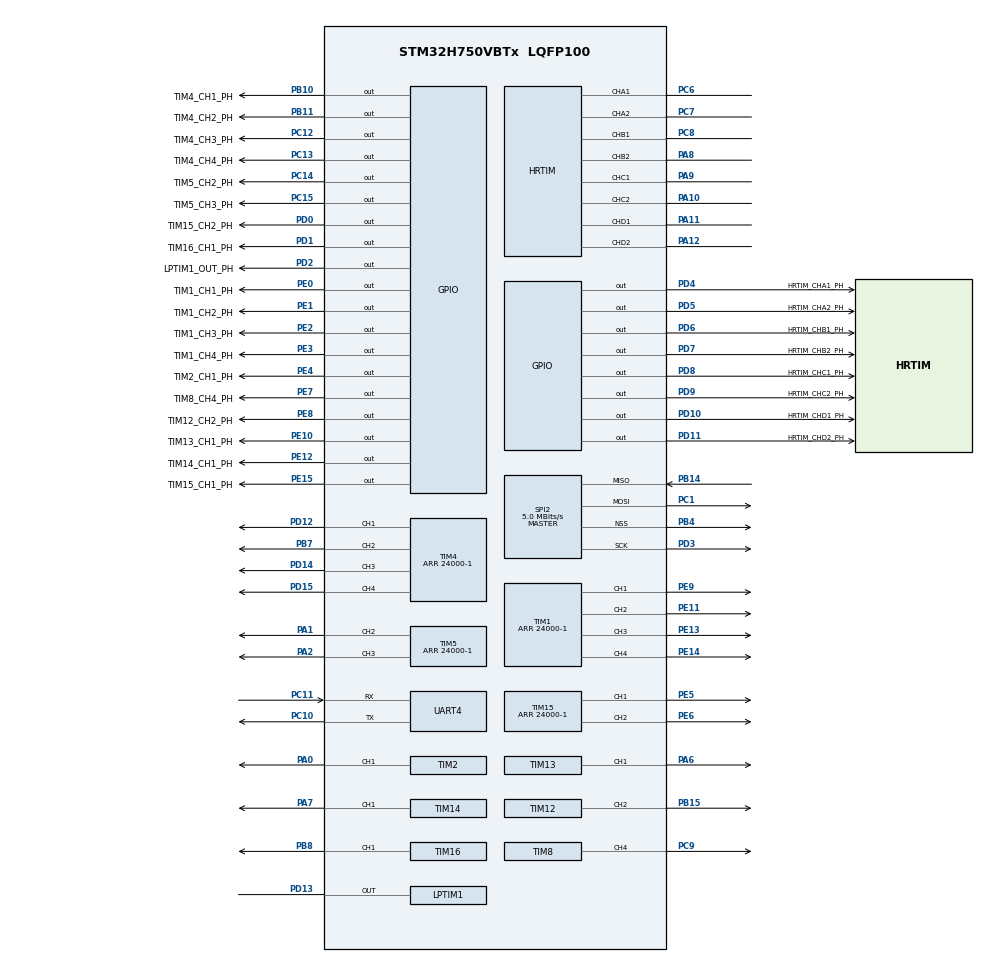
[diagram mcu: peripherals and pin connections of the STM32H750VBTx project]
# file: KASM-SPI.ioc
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CORTEX_M7.default_mode_Activation=1
HRTIM.CaptureUnit1-Output_TA1TA2=__NULL
HRTIM.CompareUnit1-Output_TA1TA2=HRTIM_COMPAREUNIT_1
HRTIM.CompareUnit1-Output_TB1TB2=HRTIM_COMPAREUNIT_1
HRTIM.CompareUnit1-Output_TC1TC2=HRTIM_COMPAREUNIT_1
HRTIM.CompareUnit1-Output_TD1TD2=HRTIM_COMPAREUNIT_1
HRTIM.CompareUnit2-Output_TA1TA2=HRTIM_COMPAREUNIT_2
HRTIM.CompareUnit2-Output_TB1TB2=HRTIM_COMPAREUNIT_2
HRTIM.CompareUnit2-Output_TC1TC2=HRTIM_COMPAREUNIT_2
HRTIM.CompareUnit2-Output_TD1TD2=HRTIM_COMPAREUNIT_2
HRTIM.CompareValue1-Output_TA1TA2=0x00005A00/2
HRTIM.CompareValue1-Output_TB1TB2=0x00005A00/2
HRTIM.CompareValue1-Output_TC1TC2=0x00005A00/2
HRTIM.CompareValue1-Output_TD1TD2=0x00005A00/2
HRTIM.CompareValue2-Output_TA1TA2=0x00005A00/2
HRTIM.CompareValue2-Output_TB1TB2=0x00005A00/2
HRTIM.CompareValue2-Output_TC1TC2=0x00005A00/2
HRTIM.CompareValue2-Output_TD1TD2=0x00005A00/2
HRTIM.Configuration_TA=Waveform
HRTIM.Enable=HRTIM_BURSTMODECTL_DISABLED
HRTIM.Event1-Output_TA1TA2=__NULL
HRTIM.Event_EEV1=HRTIM_EVENT_1
HRTIM.Event_EEV2=__NULL
HRTIM.HalfModeEnable-Output_TA1TA2=HRTIM_HALFMODE_DISABLED
HRTIM.NumberResetSource1-Output_TA1TA2=1
HRTIM.NumberResetSource1-Output_TB1TB2=1
HRTIM.NumberResetSource1-Output_TC1TC2=1
HRTIM.NumberResetSource1-Output_TD1TD2=1
HRTIM.NumberResetSource2_TA=1
HRTIM.NumberResetSource2_TB=1
HRTIM.NumberResetSource2_TC=1
HRTIM.NumberResetSource2_TD=1
HRTIM.NumberResetTrigger-Output_TA1TA2=1
HRTIM.NumberResetTrigger-Output_TB1TB2=1
HRTIM.NumberResetTrigger-Output_TC1TC2=1
HRTIM.NumberResetTrigger-Output_TD1TD2=1
HRTIM.NumberSetSource1-Output_TA1TA2=2
HRTIM.NumberSetSource1-Output_TB1TB2=2
HRTIM.NumberSetSource1-Output_TC1TC2=2
HRTIM.NumberSetSource1-Output_TD1TD2=2
HRTIM.NumberSetSource2_TA=2
HRTIM.NumberSetSource2_TB=2
HRTIM.NumberSetSource2_TC=2
HRTIM.NumberSetSource2_TD=2
HRTIM.NumberUpdateTrigger-Output_TA1TA2=0
HRTIM.Periode_TA=24000-1
HRTIM.Periode_TB=24000-1
HRTIM.Periode_TC=24000-1
HRTIM.Periode_TD=24000-1
HRTIM.Polarity1-Output_TA1TA2=HRTIM_OUTPUTPOLARITY_HIGH
HRTIM.PreloadEnable-Output_TA1TA2=HRTIM_PRELOAD_ENABLED
HRTIM.PreloadEnable-Output_TB1TB2=HRTIM_PRELOAD_ENABLED
HRTIM.PreloadEnable-Output_TC1TC2=HRTIM_PRELOAD_ENABLED
HRTIM.PreloadEnable-Output_TD1TD2=HRTIM_PRELOAD_ENABLED
HRTIM.PrescalerRatio_TA=HRTIM_PRESCALERRATIO_DIV1
HRTIM.PushPull-Output_TA1TA2=HRTIM_TIMPUSHPULLMODE_DISABLED
HRTIM.PushPull-Output_TB1TB2=HRTIM_TIMPUSHPULLMODE_DISABLED
HRTIM.RepetitionUpdate-Output_TA1TA2=HRTIM_UPDATEONREPETITION_DISABLED
HRTIM.ResetOutput1_Source1-Output_TA1TA2=HRTIM_OUTPUTRESET_TIMCMP1
HRTIM.ResetOutput1_Source1-Output_TB1TB2=HRTIM_OUTPUTRESET_TIMCMP1
HRTIM.ResetOutput1_Source1-Output_TC1TC2=HRTIM_OUTPUTRESET_TIMCMP1
HRTIM.ResetOutput1_Source1-Output_TD1TD2=HRTIM_OUTPUTRESET_TIMCMP1
HRTIM.ResetOutput2_Source1-Output_TA1TA2=HRTIM_OUTPUTRESET_TIMCMP2
HRTIM.ResetOutput2_Source1-Output_TB1TB2=HRTIM_OUTPUTRESET_TIMCMP2
HRTIM.ResetOutput2_Source1-Output_TC1TC2=HRTIM_OUTPUTRESET_TIMCMP2
HRTIM.ResetOutput2_Source1-Output_TD1TD2=HRTIM_OUTPUTRESET_TIMCMP2
HRTIM.ResetTrigger1-Output_TA1TA2=HRTIM_TIMRESETTRIGGER_EEV_1
HRTIM.ResetTrigger1-Output_TB1TB2=HRTIM_TIMRESETTRIGGER_EEV_1
HRTIM.ResetTrigger1-Output_TC1TC2=HRTIM_TIMRESETTRIGGER_EEV_1
HRTIM.ResetTrigger1-Output_TD1TD2=HRTIM_TIMRESETTRIGGER_EEV_1
HRTIM.ResetUpdate-Output_TA1TA2=HRTIM_TIMUPDATEONRESET_ENABLED
HRTIM.ResetUpdate-Output_TB1TB2=HRTIM_TIMUPDATEONRESET_ENABLED
HRTIM.ResetUpdate-Output_TC1TC2=HRTIM_TIMUPDATEONRESET_ENABLED
HRTIM.ResetUpdate-Output_TD1TD2=HRTIM_TIMUPDATEONRESET_ENABLED
HRTIM.Sensitivity_EEV1=HRTIM_EVENTSENSITIVITY_RISINGEDGE
HRTIM.SetOutput1_Source1-Output_TA1TA2=HRTIM_OUTPUTSET_EEV_1
HRTIM.SetOutput1_Source1-Output_TB1TB2=HRTIM_OUTPUTSET_EEV_1
HRTIM.SetOutput1_Source1-Output_TC1TC2=HRTIM_OUTPUTSET_EEV_1
HRTIM.SetOutput1_Source1-Output_TD1TD2=HRTIM_OUTPUTSET_EEV_1
HRTIM.SetOutput1_Source2-Output_TA1TA2=HRTIM_OUTPUTSET_TIMPER
HRTIM.SetOutput1_Source2-Output_TB1TB2=HRTIM_OUTPUTSET_TIMPER
HRTIM.SetOutput1_Source2-Output_TC1TC2=HRTIM_OUTPUTSET_TIMPER
HRTIM.SetOutput1_Source2-Output_TD1TD2=HRTIM_OUTPUTSET_TIMPER
HRTIM.SetOutput2_Source1-Output_TA1TA2=HRTIM_OUTPUTSET_EEV_1
HRTIM.SetOutput2_Source1-Output_TB1TB2=HRTIM_OUTPUTSET_EEV_1
HRTIM.SetOutput2_Source1-Output_TC1TC2=HRTIM_OUTPUTSET_EEV_1
HRTIM.SetOutput2_Source1-Output_TD1TD2=HRTIM_OUTPUTSET_EEV_1
HRTIM.SetOutput2_Source2-Output_TA1TA2=HRTIM_OUTPUTSET_TIMPER
HRTIM.SetOutput2_Source2-Output_TB1TB2=HRTIM_OUTPUTSET_TIMPER
HRTIM.SetOutput2_Source2-Output_TC1TC2=HRTIM_OUTPUTSET_TIMPER
HRTIM.SetOutput2_Source2-Output_TD1TD2=HRTIM_OUTPUTSET_TIMPER
HRTIM.Source_EEV1=HRTIM_EVENTSRC_3
HRTIM.StartOnSync-Output_TA1TA2=HRTIM_SYNCSTART_DISABLED
HRTIM.SyncOptions=HRTIM_SYNCOPTION_NONE
LPTIM1.OutputPolarity=LPTIM_OUTPUTPOLARITY_LOW
LPTIM1.TriggerSource=LPTIM_TRIGSOURCE_SOFTWARE
LPTIM1.UpdateMode=LPTIM_UPDATE_IMMEDIATE
Mcu.Family=STM32H7
Mcu.Name=STM32H750VBTx
Mcu.Package=LQFP100
NVIC.LPTIM1_IRQn=true\:0\:0\:false\:false\:true\:true\:true\:true
NVIC.PriorityGroup=NVIC_PRIORITYGROUP_4
NVIC.TIM15_IRQn=true\:0\:0\:false\:false\:true\:true\:true\:true
NVIC.TIM16_IRQn=true\:0\:0\:false\:false\:true\:true\:true\:true
NVIC.TIM1_UP_IRQn=true\:0\:0\:false\:false\:true\:true\:true\:true
NVIC.TIM2_IRQn=true\:0\:0\:false\:false\:true\:true\:true\:true
NVIC.TIM4_IRQn=true\:0\:0\:false\:false\:true\:true\:true\:true
NVIC.TIM5_IRQn=true\:0\:0\:false\:false\:true\:true\:true\:true
NVIC.TIM8_BRK_TIM12_IRQn=true\:0\:0\:false\:false\:true\:true\:true\:true
NVIC.TIM8_TRG_COM_TIM14_IRQn=true\:0\:0\:false\:false\:true\:true\:true\:true
NVIC.TIM8_UP_TIM13_IRQn=true\:0\:0\:false\:false\:true\:true\:true\:true
NVIC.UART4_IRQn=true\:0\:0\:false\:false\:true\:true\:true\:true
PA0.Signal=S_TIM2_CH1_ETR
PA1.Signal=S_TIM5_CH2
PA10.Mode=Output_TC1TC2
PA10.Signal=HRTIM_CHC2
PA11.Mode=Output_TD1TD2
PA11.Signal=HRTIM_CHD1
PA12.Mode=Output_TD1TD2
PA12.Signal=HRTIM_CHD2
PA2.Signal=S_TIM5_CH3
PA6.Signal=S_TIM13_CH1
PA7.Signal=S_TIM14_CH1
PA8.Mode=Output_TB1TB2
PA8.Signal=HRTIM_CHB2
PA9.Mode=Output_TC1TC2
PA9.Signal=HRTIM_CHC1
PB10.GPIO_Label=TIM4_CH1_PH
PB10.Signal=GPIO_Output
PB11.GPIO_Label=TIM4_CH2_PH
PB11.Signal=GPIO_Output
PB14.GPIO_Mode=GPIO_MODE_AF_PP
PB14.GPIO_PuPd=GPIO_NOPULL
PB14.GPIO_Speed=GPIO_SPEED_FREQ_VERY_HIGH
PB14.Mode=Full_Duplex_Master
PB14.Signal=SPI2_MISO
PB15.Signal=S_TIM12_CH2
PB4\ (NJTRST).Mode=NSS_Signal_Hard_Output
PB4\ (NJTRST).Signal=SPI2_NSS
PB7.Signal=S_TIM4_CH2
PB8.Signal=S_TIM16_CH1
PC1.GPIO_Mode=GPIO_MODE_AF_PP
PC1.GPIO_PuPd=GPIO_NOPULL
PC1.GPIO_Speed=GPIO_SPEED_FREQ_VERY_HIGH
PC1.Mode=Full_Duplex_Master
PC1.Signal=SPI2_MOSI
PC10.Mode=Asynchronous
PC10.Signal=UART4_TX
PC11.Mode=Asynchronous
PC11.Signal=UART4_RX
PC12.GPIO_Label=TIM4_CH3_PH
PC12.Signal=GPIO_Output
PC13.GPIO_Label=TIM4_CH4_PH
PC13.Signal=GPIO_Output
PC14-OSC32_IN\ (OSC32_IN).GPIO_Label=TIM5_CH2_PH
PC14-OSC32_IN\ (OSC32_IN).Signal=GPIO_Output
PC15-OSC32_OUT\ (OSC32_OUT).GPIO_Label=TIM5_CH3_PH
PC15-OSC32_OUT\ (OSC32_OUT).Signal=GPIO_Output
PC6.GPIO_Speed_High_Default=GPIO_SPEED_FREQ_VERY_HIGH
PC6.Mode=Output_TA1TA2
PC6.Signal=HRTIM_CHA1
PC7.GPIO_Speed_High_Default=GPIO_SPEED_FREQ_VERY_HIGH
PC7.Mode=Output_TA1TA2
PC7.Signal=HRTIM_CHA2
PC8.Mode=Output_TB1TB2
PC8.Signal=HRTIM_CHB1
PC9.Signal=S_TIM8_CH4
PD0.GPIO_Label=TIM15_CH2_PH
PD0.Signal=GPIO_Output
PD1.GPIO_Label=TIM16_CH1_PH
PD1.Signal=GPIO_Output
PD10.GPIO_Label=HRTIM_CHD1_PH
PD10.Signal=GPIO_Output
PD11.GPIO_Label=HRTIM_CHD2_PH
PD11.Signal=GPIO_Output
PD12.Signal=S_TIM4_CH1
PD13.Mode=WaveformGeneration
PD13.Signal=LPTIM1_OUT
PD14.Signal=S_TIM4_CH3
PD15.Signal=S_TIM4_CH4
PD2.GPIO_Label=LPTIM1_OUT_PH
PD2.Signal=GPIO_Output
PD3.GPIO_Mode=GPIO_MODE_AF_PP
PD3.GPIO_PuPd=GPIO_NOPULL
PD3.GPIO_Speed=GPIO_SPEED_FREQ_VERY_HIGH
PD3.Mode=Full_Duplex_Master
PD3.Signal=SPI2_SCK
PD4.GPIO_Label=HRTIM_CHA1_PH
PD4.Signal=GPIO_Output
PD5.GPIO_Label=HRTIM_CHA2_PH
PD5.Signal=GPIO_Output
PD6.GPIO_Label=HRTIM_CHB1_PH
PD6.Signal=GPIO_Output
PD7.GPIO_Label=HRTIM_CHB2_PH
PD7.Signal=GPIO_Output
PD8.GPIO_Label=HRTIM_CHC1_PH
PD8.Signal=GPIO_Output
PD9.GPIO_Label=HRTIM_CHC2_PH
PD9.Signal=GPIO_Output
PE0.GPIO_Label=TIM1_CH1_PH
PE0.Signal=GPIO_Output
PE1.GPIO_Label=TIM1_CH2_PH
PE1.Signal=GPIO_Output
PE10.GPIO_Label=TIM13_CH1_PH
PE10.Signal=GPIO_Output
PE11.Signal=S_TIM1_CH2
PE12.GPIO_Label=TIM14_CH1_PH
PE12.Signal=GPIO_Output
PE13.Signal=S_TIM1_CH3
PE14.Signal=S_TIM1_CH4
PE15.GPIO_Label=TIM15_CH1_PH
PE15.Signal=GPIO_Output
PE2.GPIO_Label=TIM1_CH3_PH
PE2.Signal=GPIO_Output
PE3.GPIO_Label=TIM1_CH4_PH
PE3.Signal=GPIO_Output
PE4.GPIO_Label=TIM2_CH1_PH
PE4.Signal=GPIO_Output
PE5.Signal=S_TIM15_CH1
PE6.Signal=S_TIM15_CH2
PE7.GPIO_Label=TIM8_CH4_PH
PE7.Signal=GPIO_Output
PE8.GPIO_Label=TIM12_CH2_PH
PE8.Signal=GPIO_Output
PE9.Signal=S_TIM1_CH1
PH0-OSC_IN\ (PH0).Mode=HSE-External-Oscillator
PH0-OSC_IN\ (PH0).Signal=RCC_OSC_IN
PH1-OSC_OUT\ (PH1).Mode=HSE-External-Oscillator
PH1-OSC_OUT\ (PH1).Signal=RCC_OSC_OUT
ProjectManager.HeapSize=0x200
ProjectManager.StackSize=0x400
ProjectManager.TargetToolchain=STM32CubeIDE
RCC.ADCFreq_Value=160000000
RCC.APB1Freq_Value=120000000
RCC.APB2Freq_Value=120000000
RCC.APB3Freq_Value=120000000
RCC.APB4Freq_Value=120000000
RCC.CortexFreq_Value=480000000
RCC.D1PPRE=RCC_APB3_DIV2
RCC.D2PPRE1=RCC_APB1_DIV2
RCC.D2PPRE2=RCC_APB2_DIV2
RCC.D3PPRE=RCC_APB4_DIV2
RCC.DIVM1=2
RCC.DIVM2=2
RCC.DIVN1=80
RCC.DIVN2=80
RCC.DIVP2=6
RCC.DIVQ1=6
RCC.DIVQ2=20
RCC.HCLKFreq_Value=240000000
RCC.HPRE=RCC_HCLK_DIV2
RCC.HSE_VALUE=24000000
RCC.PLLSourceVirtual=RCC_PLLSOURCE_HSE
RCC.RCC_TIM_PRescaler_Selection=RCC_TIMPRES_DESACTIVATED
RCC.SYSCLKFreq_VALUE=480000000
RCC.SYSCLKSource=RCC_SYSCLKSOURCE_PLLCLK
RCC.USBFreq_Value=160000000
SH.S_TIM12_CH2.0=TIM12_CH2,PWM Generation2 CH2
SH.S_TIM13_CH1.0=TIM13_CH1,PWM Generation1 CH1
SH.S_TIM14_CH1.0=TIM14_CH1,PWM Generation1 CH1
SH.S_TIM15_CH1.0=TIM15_CH1,PWM Generation1 CH1
SH.S_TIM15_CH2.0=TIM15_CH2,PWM Generation2 CH2
SH.S_TIM16_CH1.0=TIM16_CH1,PWM Generation1 CH1
SH.S_TIM1_CH1.0=TIM1_CH1,PWM Generation1 CH1
SH.S_TIM1_CH2.0=TIM1_CH2,PWM Generation2 CH2
SH.S_TIM1_CH3.0=TIM1_CH3,PWM Generation3 CH3
SH.S_TIM1_CH4.0=TIM1_CH4,PWM Generation4 CH4
SH.S_TIM2_CH1_ETR.0=TIM2_CH1,PWM Generation1 CH1
SH.S_TIM4_CH1.0=TIM4_CH1,PWM Generation1 CH1
SH.S_TIM4_CH2.0=TIM4_CH2,PWM Generation2 CH2
SH.S_TIM4_CH3.0=TIM4_CH3,PWM Generation3 CH3
SH.S_TIM4_CH4.0=TIM4_CH4,PWM Generation4 CH4
SH.S_TIM5_CH2.0=TIM5_CH2,PWM Generation2 CH2
SH.S_TIM5_CH3.0=TIM5_CH3,PWM Generation3 CH3
SH.S_TIM8_CH4.0=TIM8_CH4,PWM Generation4 CH4
SPI2.BaudRatePrescaler=SPI_BAUDRATEPRESCALER_32
SPI2.CalculateBaudRate=5.0 MBits/s
SPI2.DataSize=SPI_DATASIZE_8BIT
SPI2.Direction=SPI_DIRECTION_2LINES
SPI2.MasterKeepIOState=SPI_MASTER_KEEP_IO_STATE_ENABLE
SPI2.Mode=SPI_MODE_MASTER
SPI2.NSSPMode=SPI_NSS_PULSE_DISABLE
SPI2.VirtualNSS=VM_NSSHARD
SPI2.VirtualType=VM_MASTER
TIM1.AutoReloadPreload=TIM_AUTORELOAD_PRELOAD_ENABLE
TIM1.Channel-PWM\ Generation1\ CH1=TIM_CHANNEL_1
TIM1.Channel-PWM\ Generation2\ CH2=TIM_CHANNEL_2
TIM1.Channel-PWM\ Generation3\ CH3=TIM_CHANNEL_3
TIM1.Channel-PWM\ Generation4\ CH4=TIM_CHANNEL_4
TIM1.Period=24000-1
TIM1.TIM_MasterOutputTrigger=TIM_TRGO_UPDATE
TIM1.TIM_MasterSlaveMode=TIM_MASTERSLAVEMODE_DISABLE
TIM12.AutoReloadPreload=TIM_AUTORELOAD_PRELOAD_ENABLE
TIM12.Channel-PWM\ Generation2\ CH2=TIM_CHANNEL_2
TIM12.Period=24000-1
TIM13.AutoReloadPreload=TIM_AUTORELOAD_PRELOAD_ENABLE
TIM13.Channel=TIM_CHANNEL_1
TIM13.Period=24000-1
TIM14.AutoReloadPreload=TIM_AUTORELOAD_PRELOAD_ENABLE
TIM14.Channel=TIM_CHANNEL_1
TIM14.Period=24000-1
TIM15.AutoReloadPreload=TIM_AUTORELOAD_PRELOAD_ENABLE
TIM15.Channel-PWM\ Generation1\ CH1=TIM_CHANNEL_1
TIM15.Channel-PWM\ Generation2\ CH2=TIM_CHANNEL_2
TIM15.Period=24000-1
TIM16.AutoReloadPreload=TIM_AUTORELOAD_PRELOAD_ENABLE
TIM16.Channel=TIM_CHANNEL_1
TIM16.Period=24000-1
TIM2.AutoReloadPreload=TIM_AUTORELOAD_PRELOAD_ENABLE
TIM2.Channel-PWM\ Generation1\ CH1=TIM_CHANNEL_1
TIM2.Period=24000-1
TIM2.TIM_MasterOutputTrigger=TIM_TRGO_RESET
TIM2.TIM_MasterSlaveMode=TIM_MASTERSLAVEMODE_DISABLE
TIM4.AutoReloadPreload=TIM_AUTORELOAD_PRELOAD_ENABLE
TIM4.Channel-PWM\ Generation1\ CH1=TIM_CHANNEL_1
TIM4.Channel-PWM\ Generation2\ CH2=TIM_CHANNEL_2
TIM4.Channel-PWM\ Generation3\ CH3=TIM_CHANNEL_3
TIM4.Channel-PWM\ Generation4\ CH4=TIM_CHANNEL_4
TIM4.Period=24000-1
TIM5.AutoReloadPreload=TIM_AUTORELOAD_PRELOAD_ENABLE
TIM5.Channel-PWM\ Generation2\ CH2=TIM_CHANNEL_2
TIM5.Channel-PWM\ Generation3\ CH3=TIM_CHANNEL_3
TIM5.Period=24000-1
TIM8.AutoReloadPreload=TIM_AUTORELOAD_PRELOAD_ENABLE
TIM8.Channel-PWM\ Generation4\ CH4=TIM_CHANNEL_4
TIM8.Period=24000-1
UART4.FIFOMode=FIFOMODE_DISABLE
VP_LPTIM1_VS_LPTIM_counterModeInternalClock.Mode=Counts__internal_clock_event_00
VP_MEMORYMAP_VS_MEMORYMAP.Mode=CurAppReg
VP_TIM12_VS_ClockSourceINT.Mode=Internal
VP_TIM13_VS_ClockSourceINT.Mode=Enable_Timer
VP_TIM14_VS_ClockSourceINT.Mode=Enable_Timer
VP_TIM15_VS_ClockSourceINT.Mode=Internal
VP_TIM16_VS_ClockSourceINT.Mode=Enable_Timer
VP_TIM1_VS_ClockSourceINT.Mode=Internal
VP_TIM2_VS_ClockSourceINT.Mode=Internal
VP_TIM4_VS_ClockSourceINT.Mode=Internal
VP_TIM5_VS_ClockSourceINT.Mode=Internal
VP_TIM8_VS_ClockSourceINT.Mode=Internal
board=custom

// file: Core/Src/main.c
/* USER CODE BEGIN Header */
/**
  ******************************************************************************
  * @file           : main.c
  * @brief          : Main program body
  ******************************************************************************
  * @attention
  *
  * Copyright (c) 2025 STMicroelectronics.
  * All rights reserved.
  *
  * This software is licensed under terms that can be found in the LICENSE file
  * in the root directory of this software component.
  * If no LICENSE file comes with this software, it is provided AS-IS.
  *
  ******************************************************************************
  */
/* USER CODE END Header */
#include "main.h"

/* USER CODE BEGIN PM */
/* uncomment below for client board */
#define MASTER_BOARD

/* USER CODE END PM */

HRTIM_HandleTypeDef hhrtim;

LPTIM_HandleTypeDef hlptim1;

SPI_HandleTypeDef hspi2;

TIM_HandleTypeDef htim1;
TIM_HandleTypeDef htim2;
TIM_HandleTypeDef htim4;
TIM_HandleTypeDef htim5;
TIM_HandleTypeDef htim8;
TIM_HandleTypeDef htim12;
TIM_HandleTypeDef htim13;
TIM_HandleTypeDef htim14;
TIM_HandleTypeDef htim15;
TIM_HandleTypeDef htim16;

/* USER CODE BEGIN PV */
/* Buffer used for transmission */
uint8_t TX_Buffer[] = "****SPI - Two Boards communication based on Polling **** SPI Message ******** SPI Message ******** SPI Message ****";

/* Buffer used for reception */
uint8_t RX_Buffer[BUFFERSIZE];
/* USER CODE END PV */

void SystemClock_Config(void);
static void MPU_Config(void);
static void MX_GPIO_Init(void);
static void MX_TIM1_Init(void);
static void MX_TIM2_Init(void);
static void MX_TIM4_Init(void);
static void MX_TIM5_Init(void);
static void MX_TIM8_Init(void);
static void MX_TIM12_Init(void);
static void MX_TIM13_Init(void);
static void MX_TIM14_Init(void);
static void MX_TIM15_Init(void);
static void MX_TIM16_Init(void);
static void MX_HRTIM_Init(void);
static void MX_LPTIM1_Init(void);
static void MX_UART4_Init(void);
static void MX_SPI2_Init(void);
/* USER CODE BEGIN PFP */
/**
* @brief CPU L1-Cache enable.
* @param None
* @retval None
*/
static void CPU_CACHE_Enable(void);

/**
  * @brief  Compares two buffers.
  * @param  pBuffer1, pBuffer2: buffers to be compared.
  * @param  BufferLength: buffer's length
  * @retval 0  : pBuffer1 identical to pBuffer2
  *         >0 : pBuffer1 differs from pBuffer2
  */
static uint16_t Buffercmp(uint8_t* pBuffer1, uint8_t* pBuffer2, uint16_t BufferLength);

/* USER CODE END PFP */

int main(void)
{

  /* MPU Configuration--------------------------------------------------------*/
  MPU_Config();

  /* MCU Configuration--------------------------------------------------------*/

  /* Reset of all peripherals, Initializes the Flash interface and the Systick. */
  HAL_Init();

  /* Configure the system clock */
  SystemClock_Config();

  /* Initialize all configured peripherals */
  MX_GPIO_Init();
  MX_TIM1_Init();
  MX_TIM2_Init();
  MX_TIM4_Init();
  MX_TIM5_Init();
  MX_TIM8_Init();
  MX_TIM12_Init();
  MX_TIM13_Init();
  MX_TIM14_Init();
  MX_TIM15_Init();
  MX_TIM16_Init();
  MX_HRTIM_Init();
  MX_LPTIM1_Init();
  MX_UART4_Init();
  MX_SPI2_Init();

  /* Infinite loop */
  /* USER CODE BEGIN WHILE */
  while (1)
  {

	  /* While the SPI in TransmitReceive process, user can transmit data through
	     "TX_Buffer" buffer & receive data through "RX_Buffer" */
	  /* Timeout is set to 5S */

	  switch(HAL_SPI_TransmitReceive(&hspi2, (uint8_t*)TX_Buffer, (uint8_t *)RX_Buffer, BUFFERSIZE, 5000))
	  {
	    case HAL_OK:
	      /* Communication is completed ___________________________________________ */
	      /* Compare the sent and received buffers */
//	      if (Buffercmp((uint8_t *)TX_Buffer, (uint8_t *)RX_Buffer, BUFFERSIZE))
//	      {
//	        /* Transfer error in transmission process */
//	        Error_Handler();
//	      }
	      break;

	    case HAL_TIMEOUT:
	      /* A Timeout Occur ______________________________________________________*/
	      /* Call Timeout Handler */
	    	HAL_Delay(1);
	    	Error_Handler();
	      break;
	      /* An Error Occur ______________________________________________________ */
	    case HAL_ERROR:
	      /* Call Error Handler */
	      Error_Handler();
	      break;
	    default:
	      break;
	  }

	  HAL_Delay(100); // wait a couple seconds
    /* USER CODE END WHILE */

  }
}

void SystemClock_Config(void)
{
  RCC_OscInitTypeDef RCC_OscInitStruct = {0};
  RCC_ClkInitTypeDef RCC_ClkInitStruct = {0};

  /** Supply configuration update enable
  */
  HAL_PWREx_ConfigSupply(PWR_LDO_SUPPLY);

  /** Configure the main internal regulator output voltage
  */
  __HAL_PWR_VOLTAGESCALING_CONFIG(PWR_REGULATOR_VOLTAGE_SCALE0);

  while(!__HAL_PWR_GET_FLAG(PWR_FLAG_VOSRDY)) {}

  /** Initializes the RCC Oscillators according to the specified parameters
  * in the RCC_OscInitTypeDef structure.
  */
  RCC_OscInitStruct.OscillatorType = RCC_OSCILLATORTYPE_HSE;
  RCC_OscInitStruct.HSEState = RCC_HSE_ON;
  RCC_OscInitStruct.PLL.PLLState = RCC_PLL_ON;
  RCC_OscInitStruct.PLL.PLLSource = RCC_PLLSOURCE_HSE;
  RCC_OscInitStruct.PLL.PLLM = 2;
  RCC_OscInitStruct.PLL.PLLN = 80;
  RCC_OscInitStruct.PLL.PLLP = 2;
  RCC_OscInitStruct.PLL.PLLQ = 6;
  RCC_OscInitStruct.PLL.PLLR = 2;
  RCC_OscInitStruct.PLL.PLLRGE = RCC_PLL1VCIRANGE_3;
  RCC_OscInitStruct.PLL.PLLVCOSEL = RCC_PLL1VCOWIDE;
  RCC_OscInitStruct.PLL.PLLFRACN = 0;
  if (HAL_RCC_OscConfig(&RCC_OscInitStruct) != HAL_OK)
  {
    Error_Handler();
  }

  /** Initializes the CPU, AHB and APB buses clocks
  */
  RCC_ClkInitStruct.ClockType = RCC_CLOCKTYPE_HCLK|RCC_CLOCKTYPE_SYSCLK
                              |RCC_CLOCKTYPE_PCLK1|RCC_CLOCKTYPE_PCLK2
                              |RCC_CLOCKTYPE_D3PCLK1|RCC_CLOCKTYPE_D1PCLK1;
  RCC_ClkInitStruct.SYSCLKSource = RCC_SYSCLKSOURCE_PLLCLK;
  RCC_ClkInitStruct.SYSCLKDivider = RCC_SYSCLK_DIV1;
  RCC_ClkInitStruct.AHBCLKDivider = RCC_HCLK_DIV2;
  RCC_ClkInitStruct.APB3CLKDivider = RCC_APB3_DIV2;
  RCC_ClkInitStruct.APB1CLKDivider = RCC_APB1_DIV2;
  RCC_ClkInitStruct.APB2CLKDivider = RCC_APB2_DIV2;
  RCC_ClkInitStruct.APB4CLKDivider = RCC_APB4_DIV2;

  if (HAL_RCC_ClockConfig(&RCC_ClkInitStruct, FLASH_LATENCY_4) != HAL_OK)
  {
    Error_Handler();
  }
}

static void MX_HRTIM_Init(void)
{

  HRTIM_EventCfgTypeDef pEventCfg = {0};
  HRTIM_TimeBaseCfgTypeDef pTimeBaseCfg = {0};
  HRTIM_TimerCfgTypeDef pTimerCfg = {0};
  HRTIM_CompareCfgTypeDef pCompareCfg = {0};
  HRTIM_OutputCfgTypeDef pOutputCfg = {0};

  hhrtim.Instance = HRTIM1;
  hhrtim.Init.HRTIMInterruptResquests = HRTIM_IT_NONE;
  hhrtim.Init.SyncOptions = HRTIM_SYNCOPTION_NONE;
  if (HAL_HRTIM_Init(&hhrtim) != HAL_OK)
  {
    Error_Handler();
  }
  if (HAL_HRTIM_EventPrescalerConfig(&hhrtim, HRTIM_EVENTPRESCALER_DIV1) != HAL_OK)
  {
    Error_Handler();
  }
  pEventCfg.Source = HRTIM_EVENTSRC_3;
  pEventCfg.Polarity = HRTIM_EVENTPOLARITY_HIGH;
  pEventCfg.Sensitivity = HRTIM_EVENTSENSITIVITY_RISINGEDGE;
  pEventCfg.FastMode = HRTIM_EVENTFASTMODE_DISABLE;
  if (HAL_HRTIM_EventConfig(&hhrtim, HRTIM_EVENT_1, &pEventCfg) != HAL_OK)
  {
    Error_Handler();
  }
  pTimeBaseCfg.Period = 24000-1;
  pTimeBaseCfg.RepetitionCounter = 0x00;
  pTimeBaseCfg.PrescalerRatio = HRTIM_PRESCALERRATIO_DIV1;
  pTimeBaseCfg.Mode = HRTIM_MODE_CONTINUOUS;
  if (HAL_HRTIM_TimeBaseConfig(&hhrtim, HRTIM_TIMERINDEX_TIMER_A, &pTimeBaseCfg) != HAL_OK)
  {
    Error_Handler();
  }
  pTimerCfg.InterruptRequests = HRTIM_TIM_IT_NONE;
  pTimerCfg.DMARequests = HRTIM_TIM_DMA_NONE;
  pTimerCfg.DMASrcAddress = 0x0000;
  pTimerCfg.DMADstAddress = 0x0000;
  pTimerCfg.DMASize = 0x1;
  pTimerCfg.HalfModeEnable = HRTIM_HALFMODE_DISABLED;
  pTimerCfg.StartOnSync = HRTIM_SYNCSTART_DISABLED;
  pTimerCfg.ResetOnSync = HRTIM_SYNCRESET_DISABLED;
  pTimerCfg.DACSynchro = HRTIM_DACSYNC_NONE;
  pTimerCfg.PreloadEnable = HRTIM_PRELOAD_ENABLED;
  pTimerCfg.UpdateGating = HRTIM_UPDATEGATING_INDEPENDENT;
  pTimerCfg.BurstMode = HRTIM_TIMERBURSTMODE_MAINTAINCLOCK;
  pTimerCfg.RepetitionUpdate = HRTIM_UPDATEONREPETITION_DISABLED;
  pTimerCfg.PushPull = HRTIM_TIMPUSHPULLMODE_DISABLED;
  pTimerCfg.FaultEnable = HRTIM_TIMFAULTENABLE_NONE;
  pTimerCfg.FaultLock = HRTIM_TIMFAULTLOCK_READWRITE;
  pTimerCfg.DeadTimeInsertion = HRTIM_TIMDEADTIMEINSERTION_DISABLED;
  pTimerCfg.DelayedProtectionMode = HRTIM_TIMER_A_B_C_DELAYEDPROTECTION_DISABLED;
  pTimerCfg.UpdateTrigger = HRTIM_TIMUPDATETRIGGER_NONE;
  pTimerCfg.ResetTrigger = HRTIM_TIMRESETTRIGGER_EEV_1;
  pTimerCfg.ResetUpdate = HRTIM_TIMUPDATEONRESET_ENABLED;
  if (HAL_HRTIM_WaveformTimerConfig(&hhrtim, HRTIM_TIMERINDEX_TIMER_A, &pTimerCfg) != HAL_OK)
  {
    Error_Handler();
  }
  if (HAL_HRTIM_WaveformTimerConfig(&hhrtim, HRTIM_TIMERINDEX_TIMER_B, &pTimerCfg) != HAL_OK)
  {
    Error_Handler();
  }
  if (HAL_HRTIM_WaveformTimerConfig(&hhrtim, HRTIM_TIMERINDEX_TIMER_C, &pTimerCfg) != HAL_OK)
  {
    Error_Handler();
  }
  pTimerCfg.DelayedProtectionMode = HRTIM_TIMER_D_E_DELAYEDPROTECTION_DISABLED;
  if (HAL_HRTIM_WaveformTimerConfig(&hhrtim, HRTIM_TIMERINDEX_TIMER_D, &pTimerCfg) != HAL_OK)
  {
    Error_Handler();
  }
  pCompareCfg.CompareValue = 0x00005A00/2;
  if (HAL_HRTIM_WaveformCompareConfig(&hhrtim, HRTIM_TIMERINDEX_TIMER_A, HRTIM_COMPAREUNIT_1, &pCompareCfg) != HAL_OK)
  {
    Error_Handler();
  }
  pCompareCfg.AutoDelayedMode = HRTIM_AUTODELAYEDMODE_REGULAR;
  pCompareCfg.AutoDelayedTimeout = 0x0000;

  if (HAL_HRTIM_WaveformCompareConfig(&hhrtim, HRTIM_TIMERINDEX_TIMER_A, HRTIM_COMPAREUNIT_2, &pCompareCfg) != HAL_OK)
  {
    Error_Handler();
  }

  if (HAL_HRTIM_WaveformCompareConfig(&hhrtim, HRTIM_TIMERINDEX_TIMER_B, HRTIM_COMPAREUNIT_2, &pCompareCfg) != HAL_OK)
  {
    Error_Handler();
  }

  if (HAL_HRTIM_WaveformCompareConfig(&hhrtim, HRTIM_TIMERINDEX_TIMER_C, HRTIM_COMPAREUNIT_2, &pCompareCfg) != HAL_OK)
  {
    Error_Handler();
  }

  if (HAL_HRTIM_WaveformCompareConfig(&hhrtim, HRTIM_TIMERINDEX_TIMER_D, HRTIM_COMPAREUNIT_2, &pCompareCfg) != HAL_OK)
  {
    Error_Handler();
  }
  pOutputCfg.Polarity = HRTIM_OUTPUTPOLARITY_HIGH;
  pOutputCfg.SetSource = HRTIM_OUTPUTSET_EEV_1|HRTIM_OUTPUTSET_TIMPER;
  pOutputCfg.ResetSource = HRTIM_OUTPUTRESET_TIMCMP1;
  pOutputCfg.IdleMode = HRTIM_OUTPUTIDLEMODE_NONE;
  pOutputCfg.IdleLevel = HRTIM_OUTPUTIDLELEVEL_INACTIVE;
  pOutputCfg.FaultLevel = HRTIM_OUTPUTFAULTLEVEL_NONE;
  pOutputCfg.ChopperModeEnable = HRTIM_OUTPUTCHOPPERMODE_DISABLED;
  pOutputCfg.BurstModeEntryDelayed = HRTIM_OUTPUTBURSTMODEENTRY_REGULAR;
  if (HAL_HRTIM_WaveformOutputConfig(&hhrtim, HRTIM_TIMERINDEX_TIMER_A, HRTIM_OUTPUT_TA1, &pOutputCfg) != HAL_OK)
  {
    Error_Handler();
  }
  if (HAL_HRTIM_WaveformOutputConfig(&hhrtim, HRTIM_TIMERINDEX_TIMER_B, HRTIM_OUTPUT_TB1, &pOutputCfg) != HAL_OK)
  {
    Error_Handler();
  }
  if (HAL_HRTIM_WaveformOutputConfig(&hhrtim, HRTIM_TIMERINDEX_TIMER_C, HRTIM_OUTPUT_TC1, &pOutputCfg) != HAL_OK)
  {
    Error_Handler();
  }
  if (HAL_HRTIM_WaveformOutputConfig(&hhrtim, HRTIM_TIMERINDEX_TIMER_D, HRTIM_OUTPUT_TD1, &pOutputCfg) != HAL_OK)
  {
    Error_Handler();
  }
  pOutputCfg.ResetSource = HRTIM_OUTPUTRESET_TIMCMP2;
  if (HAL_HRTIM_WaveformOutputConfig(&hhrtim, HRTIM_TIMERINDEX_TIMER_A, HRTIM_OUTPUT_TA2, &pOutputCfg) != HAL_OK)
  {
    Error_Handler();
  }
  if (HAL_HRTIM_WaveformOutputConfig(&hhrtim, HRTIM_TIMERINDEX_TIMER_B, HRTIM_OUTPUT_TB2, &pOutputCfg) != HAL_OK)
  {
    Error_Handler();
  }
  if (HAL_HRTIM_WaveformOutputConfig(&hhrtim, HRTIM_TIMERINDEX_TIMER_C, HRTIM_OUTPUT_TC2, &pOutputCfg) != HAL_OK)
  {
    Error_Handler();
  }
  if (HAL_HRTIM_WaveformOutputConfig(&hhrtim, HRTIM_TIMERINDEX_TIMER_D, HRTIM_OUTPUT_TD2, &pOutputCfg) != HAL_OK)
  {
    Error_Handler();
  }
  if (HAL_HRTIM_TimeBaseConfig(&hhrtim, HRTIM_TIMERINDEX_TIMER_B, &pTimeBaseCfg) != HAL_OK)
  {
    Error_Handler();
  }
  if (HAL_HRTIM_WaveformCompareConfig(&hhrtim, HRTIM_TIMERINDEX_TIMER_B, HRTIM_COMPAREUNIT_1, &pCompareCfg) != HAL_OK)
  {
    Error_Handler();
  }
  if (HAL_HRTIM_TimeBaseConfig(&hhrtim, HRTIM_TIMERINDEX_TIMER_C, &pTimeBaseCfg) != HAL_OK)
  {
    Error_Handler();
  }
  if (HAL_HRTIM_WaveformCompareConfig(&hhrtim, HRTIM_TIMERINDEX_TIMER_C, HRTIM_COMPAREUNIT_1, &pCompareCfg) != HAL_OK)
  {
    Error_Handler();
  }
  if (HAL_HRTIM_TimeBaseConfig(&hhrtim, HRTIM_TIMERINDEX_TIMER_D, &pTimeBaseCfg) != HAL_OK)
  {
    Error_Handler();
  }
  if (HAL_HRTIM_WaveformCompareConfig(&hhrtim, HRTIM_TIMERINDEX_TIMER_D, HRTIM_COMPAREUNIT_1, &pCompareCfg) != HAL_OK)
  {
    Error_Handler();
  }
  HAL_HRTIM_MspPostInit(&hhrtim);

}

static void MX_LPTIM1_Init(void)
{

  hlptim1.Instance = LPTIM1;
  hlptim1.Init.Clock.Source = LPTIM_CLOCKSOURCE_APBCLOCK_LPOSC;
  hlptim1.Init.Clock.Prescaler = LPTIM_PRESCALER_DIV1;
  hlptim1.Init.Trigger.Source = LPTIM_TRIGSOURCE_SOFTWARE;
  hlptim1.Init.OutputPolarity = LPTIM_OUTPUTPOLARITY_LOW;
  hlptim1.Init.UpdateMode = LPTIM_UPDATE_IMMEDIATE;
  hlptim1.Init.CounterSource = LPTIM_COUNTERSOURCE_INTERNAL;
  hlptim1.Init.Input1Source = LPTIM_INPUT1SOURCE_GPIO;
  hlptim1.Init.Input2Source = LPTIM_INPUT2SOURCE_GPIO;
  if (HAL_LPTIM_Init(&hlptim1) != HAL_OK)
  {
    Error_Handler();
  }

}

static void MX_SPI2_Init(void)
{

  /* USER CODE BEGIN SPI2_Init 1 */
#ifdef MASTER_BOARD
  hspi2.Init.Mode = SPI_MODE_MASTER;
#else
  hspi2.Init.Mode = SPI_MODE_SLAVE;
#endif /* MASTER_BOARD */

  /* USER CODE END SPI2_Init 1 */
  /* SPI2 parameter configuration*/
  hspi2.Instance = SPI2;
  hspi2.Init.Mode = SPI_MODE_MASTER;
  hspi2.Init.Direction = SPI_DIRECTION_2LINES;
  hspi2.Init.DataSize = SPI_DATASIZE_8BIT;
  hspi2.Init.CLKPolarity = SPI_POLARITY_LOW;
  hspi2.Init.CLKPhase = SPI_PHASE_1EDGE;
  hspi2.Init.NSS = SPI_NSS_HARD_OUTPUT;
  hspi2.Init.BaudRatePrescaler = SPI_BAUDRATEPRESCALER_32;
  hspi2.Init.FirstBit = SPI_FIRSTBIT_MSB;
  hspi2.Init.TIMode = SPI_TIMODE_DISABLE;
  hspi2.Init.CRCCalculation = SPI_CRCCALCULATION_DISABLE;
  hspi2.Init.CRCPolynomial = 0x0;
  hspi2.Init.NSSPMode = SPI_NSS_PULSE_DISABLE;
  hspi2.Init.NSSPolarity = SPI_NSS_POLARITY_LOW;
  hspi2.Init.FifoThreshold = SPI_FIFO_THRESHOLD_01DATA;
  hspi2.Init.TxCRCInitializationPattern = SPI_CRC_INITIALIZATION_ALL_ZERO_PATTERN;
  hspi2.Init.RxCRCInitializationPattern = SPI_CRC_INITIALIZATION_ALL_ZERO_PATTERN;
  hspi2.Init.MasterSSIdleness = SPI_MASTER_SS_IDLENESS_00CYCLE;
  hspi2.Init.MasterInterDataIdleness = SPI_MASTER_INTERDATA_IDLENESS_00CYCLE;
  hspi2.Init.MasterReceiverAutoSusp = SPI_MASTER_RX_AUTOSUSP_DISABLE;
  hspi2.Init.MasterKeepIOState = SPI_MASTER_KEEP_IO_STATE_ENABLE;
  hspi2.Init.IOSwap = SPI_IO_SWAP_DISABLE;
  if (HAL_SPI_Init(&hspi2) != HAL_OK)
  {
    Error_Handler();
  }

}

static void MX_TIM1_Init(void)
{

  TIM_ClockConfigTypeDef sClockSourceConfig = {0};
  TIM_MasterConfigTypeDef sMasterConfig = {0};
  TIM_OC_InitTypeDef sConfigOC = {0};
  TIM_BreakDeadTimeConfigTypeDef sBreakDeadTimeConfig = {0};

  htim1.Instance = TIM1;
  htim1.Init.Prescaler = 0;
  htim1.Init.CounterMode = TIM_COUNTERMODE_UP;
  htim1.Init.Period = 24000-1;
  htim1.Init.ClockDivision = TIM_CLOCKDIVISION_DIV1;
  htim1.Init.RepetitionCounter = 0;
  htim1.Init.AutoReloadPreload = TIM_AUTORELOAD_PRELOAD_ENABLE;
  if (HAL_TIM_Base_Init(&htim1) != HAL_OK)
  {
    Error_Handler();
  }
  sClockSourceConfig.ClockSource = TIM_CLOCKSOURCE_INTERNAL;
  if (HAL_TIM_ConfigClockSource(&htim1, &sClockSourceConfig) != HAL_OK)
  {
    Error_Handler();
  }
  if (HAL_TIM_PWM_Init(&htim1) != HAL_OK)
  {
    Error_Handler();
  }
  sMasterConfig.MasterOutputTrigger = TIM_TRGO_UPDATE;
  sMasterConfig.MasterOutputTrigger2 = TIM_TRGO2_RESET;
  sMasterConfig.MasterSlaveMode = TIM_MASTERSLAVEMODE_DISABLE;
  if (HAL_TIMEx_MasterConfigSynchronization(&htim1, &sMasterConfig) != HAL_OK)
  {
    Error_Handler();
  }
  sConfigOC.OCMode = TIM_OCMODE_PWM1;
  sConfigOC.Pulse = 0;
  sConfigOC.OCPolarity = TIM_OCPOLARITY_HIGH;
  sConfigOC.OCNPolarity = TIM_OCNPOLARITY_HIGH;
  sConfigOC.OCFastMode = TIM_OCFAST_DISABLE;
  sConfigOC.OCIdleState = TIM_OCIDLESTATE_RESET;
  sConfigOC.OCNIdleState = TIM_OCNIDLESTATE_RESET;
  if (HAL_TIM_PWM_ConfigChannel(&htim1, &sConfigOC, TIM_CHANNEL_1) != HAL_OK)
  {
    Error_Handler();
  }
  if (HAL_TIM_PWM_ConfigChannel(&htim1, &sConfigOC, TIM_CHANNEL_2) != HAL_OK)
  {
    Error_Handler();
  }
  if (HAL_TIM_PWM_ConfigChannel(&htim1, &sConfigOC, TIM_CHANNEL_3) != HAL_OK)
  {
    Error_Handler();
  }
  if (HAL_TIM_PWM_ConfigChannel(&htim1, &sConfigOC, TIM_CHANNEL_4) != HAL_OK)
  {
    Error_Handler();
  }
  sBreakDeadTimeConfig.OffStateRunMode = TIM_OSSR_DISABLE;
  sBreakDeadTimeConfig.OffStateIDLEMode = TIM_OSSI_DISABLE;
  sBreakDeadTimeConfig.LockLevel = TIM_LOCKLEVEL_OFF;
  sBreakDeadTimeConfig.DeadTime = 0;
  sBreakDeadTimeConfig.BreakState = TIM_BREAK_DISABLE;
  sBreakDeadTimeConfig.BreakPolarity = TIM_BREAKPOLARITY_HIGH;
  sBreakDeadTimeConfig.BreakFilter = 0;
  sBreakDeadTimeConfig.Break2State = TIM_BREAK2_DISABLE;
  sBreakDeadTimeConfig.Break2Polarity = TIM_BREAK2POLARITY_HIGH;
  sBreakDeadTimeConfig.Break2Filter = 0;
  sBreakDeadTimeConfig.AutomaticOutput = TIM_AUTOMATICOUTPUT_DISABLE;
  if (HAL_TIMEx_ConfigBreakDeadTime(&htim1, &sBreakDeadTimeConfig) != HAL_OK)
  {
    Error_Handler();
  }
  HAL_TIM_MspPostInit(&htim1);

}

static void MX_TIM2_Init(void)
{

  TIM_ClockConfigTypeDef sClockSourceConfig = {0};
  TIM_MasterConfigTypeDef sMasterConfig = {0};
  TIM_OC_InitTypeDef sConfigOC = {0};

  htim2.Instance = TIM2;
  htim2.Init.Prescaler = 0;
  htim2.Init.CounterMode = TIM_COUNTERMODE_UP;
  htim2.Init.Period = 24000-1;
  htim2.Init.ClockDivision = TIM_CLOCKDIVISION_DIV1;
  htim2.Init.AutoReloadPreload = TIM_AUTORELOAD_PRELOAD_ENABLE;
  if (HAL_TIM_Base_Init(&htim2) != HAL_OK)
  {
    Error_Handler();
  }
  sClockSourceConfig.ClockSource = TIM_CLOCKSOURCE_INTERNAL;
  if (HAL_TIM_ConfigClockSource(&htim2, &sClockSourceConfig) != HAL_OK)
  {
    Error_Handler();
  }
  if (HAL_TIM_PWM_Init(&htim2) != HAL_OK)
  {
    Error_Handler();
  }
  sMasterConfig.MasterOutputTrigger = TIM_TRGO_RESET;
  sMasterConfig.MasterSlaveMode = TIM_MASTERSLAVEMODE_DISABLE;
  if (HAL_TIMEx_MasterConfigSynchronization(&htim2, &sMasterConfig) != HAL_OK)
  {
    Error_Handler();
  }
  sConfigOC.OCMode = TIM_OCMODE_PWM1;
  sConfigOC.Pulse = 0;
  sConfigOC.OCPolarity = TIM_OCPOLARITY_HIGH;
  sConfigOC.OCFastMode = TIM_OCFAST_DISABLE;
  if (HAL_TIM_PWM_ConfigChannel(&htim2, &sConfigOC, TIM_CHANNEL_1) != HAL_OK)
  {
    Error_Handler();
  }
  HAL_TIM_MspPostInit(&htim2);

}

static void MX_TIM4_Init(void)
{

  TIM_ClockConfigTypeDef sClockSourceConfig = {0};
  TIM_MasterConfigTypeDef sMasterConfig = {0};
  TIM_OC_InitTypeDef sConfigOC = {0};

  htim4.Instance = TIM4;
  htim4.Init.Prescaler = 0;
  htim4.Init.CounterMode = TIM_COUNTERMODE_UP;
  htim4.Init.Period = 24000-1;
  htim4.Init.ClockDivision = TIM_CLOCKDIVISION_DIV1;
  htim4.Init.AutoReloadPreload = TIM_AUTORELOAD_PRELOAD_ENABLE;
  if (HAL_TIM_Base_Init(&htim4) != HAL_OK)
  {
    Error_Handler();
  }
  sClockSourceConfig.ClockSource = TIM_CLOCKSOURCE_INTERNAL;
  if (HAL_TIM_ConfigClockSource(&htim4, &sClockSourceConfig) != HAL_OK)
  {
    Error_Handler();
  }
  if (HAL_TIM_PWM_Init(&htim4) != HAL_OK)
  {
    Error_Handler();
  }
  sMasterConfig.MasterOutputTrigger = TIM_TRGO_RESET;
  sMasterConfig.MasterSlaveMode = TIM_MASTERSLAVEMODE_DISABLE;
  if (HAL_TIMEx_MasterConfigSynchronization(&htim4, &sMasterConfig) != HAL_OK)
  {
    Error_Handler();
  }
  sConfigOC.OCMode = TIM_OCMODE_PWM1;
  sConfigOC.Pulse = 0;
  sConfigOC.OCPolarity = TIM_OCPOLARITY_HIGH;
  sConfigOC.OCFastMode = TIM_OCFAST_DISABLE;
  if (HAL_TIM_PWM_ConfigChannel(&htim4, &sConfigOC, TIM_CHANNEL_1) != HAL_OK)
  {
    Error_Handler();
  }
  if (HAL_TIM_PWM_ConfigChannel(&htim4, &sConfigOC, TIM_CHANNEL_2) != HAL_OK)
  {
    Error_Handler();
  }
  if (HAL_TIM_PWM_ConfigChannel(&htim4, &sConfigOC, TIM_CHANNEL_3) != HAL_OK)
  {
    Error_Handler();
  }
  if (HAL_TIM_PWM_ConfigChannel(&htim4, &sConfigOC, TIM_CHANNEL_4) != HAL_OK)
  {
    Error_Handler();
  }
  HAL_TIM_MspPostInit(&htim4);

}

static void MX_TIM5_Init(void)
{

  TIM_ClockConfigTypeDef sClockSourceConfig = {0};
  TIM_MasterConfigTypeDef sMasterConfig = {0};
  TIM_OC_InitTypeDef sConfigOC = {0};

  htim5.Instance = TIM5;
  htim5.Init.Prescaler = 0;
  htim5.Init.CounterMode = TIM_COUNTERMODE_UP;
  htim5.Init.Period = 24000-1;
  htim5.Init.ClockDivision = TIM_CLOCKDIVISION_DIV1;
  htim5.Init.AutoReloadPreload = TIM_AUTORELOAD_PRELOAD_ENABLE;
  if (HAL_TIM_Base_Init(&htim5) != HAL_OK)
  {
    Error_Handler();
  }
  sClockSourceConfig.ClockSource = TIM_CLOCKSOURCE_INTERNAL;
  if (HAL_TIM_ConfigClockSource(&htim5, &sClockSourceConfig) != HAL_OK)
  {
    Error_Handler();
  }
  if (HAL_TIM_PWM_Init(&htim5) != HAL_OK)
  {
    Error_Handler();
  }
  sMasterConfig.MasterOutputTrigger = TIM_TRGO_RESET;
  sMasterConfig.MasterSlaveMode = TIM_MASTERSLAVEMODE_DISABLE;
  if (HAL_TIMEx_MasterConfigSynchronization(&htim5, &sMasterConfig) != HAL_OK)
  {
    Error_Handler();
  }
  sConfigOC.OCMode = TIM_OCMODE_PWM1;
  sConfigOC.Pulse = 0;
  sConfigOC.OCPolarity = TIM_OCPOLARITY_HIGH;
  sConfigOC.OCFastMode = TIM_OCFAST_DISABLE;
  if (HAL_TIM_PWM_ConfigChannel(&htim5, &sConfigOC, TIM_CHANNEL_2) != HAL_OK)
  {
    Error_Handler();
  }
  if (HAL_TIM_PWM_ConfigChannel(&htim5, &sConfigOC, TIM_CHANNEL_3) != HAL_OK)
  {
    Error_Handler();
  }
  HAL_TIM_MspPostInit(&htim5);

}

static void MX_TIM8_Init(void)
{

  TIM_ClockConfigTypeDef sClockSourceConfig = {0};
  TIM_MasterConfigTypeDef sMasterConfig = {0};
  TIM_OC_InitTypeDef sConfigOC = {0};
  TIM_BreakDeadTimeConfigTypeDef sBreakDeadTimeConfig = {0};

  htim8.Instance = TIM8;
  htim8.Init.Prescaler = 0;
  htim8.Init.CounterMode = TIM_COUNTERMODE_UP;
  htim8.Init.Period = 24000-1;
  htim8.Init.ClockDivision = TIM_CLOCKDIVISION_DIV1;
  htim8.Init.RepetitionCounter = 0;
  htim8.Init.AutoReloadPreload = TIM_AUTORELOAD_PRELOAD_ENABLE;
  if (HAL_TIM_Base_Init(&htim8) != HAL_OK)
  {
    Error_Handler();
  }
  sClockSourceConfig.ClockSource = TIM_CLOCKSOURCE_INTERNAL;
  if (HAL_TIM_ConfigClockSource(&htim8, &sClockSourceConfig) != HAL_OK)
  {
    Error_Handler();
  }
  if (HAL_TIM_PWM_Init(&htim8) != HAL_OK)
  {
    Error_Handler();
  }
  sMasterConfig.MasterOutputTrigger = TIM_TRGO_RESET;
  sMasterConfig.MasterOutputTrigger2 = TIM_TRGO2_RESET;
  sMasterConfig.MasterSlaveMode = TIM_MASTERSLAVEMODE_DISABLE;
  if (HAL_TIMEx_MasterConfigSynchronization(&htim8, &sMasterConfig) != HAL_OK)
  {
    Error_Handler();
  }
  sConfigOC.OCMode = TIM_OCMODE_PWM1;
  sConfigOC.Pulse = 0;
  sConfigOC.OCPolarity = TIM_OCPOLARITY_HIGH;
  sConfigOC.OCFastMode = TIM_OCFAST_DISABLE;
  sConfigOC.OCIdleState = TIM_OCIDLESTATE_RESET;
  sConfigOC.OCNIdleState = TIM_OCNIDLESTATE_RESET;
  if (HAL_TIM_PWM_ConfigChannel(&htim8, &sConfigOC, TIM_CHANNEL_4) != HAL_OK)
  {
    Error_Handler();
  }
  sBreakDeadTimeConfig.OffStateRunMode = TIM_OSSR_DISABLE;
  sBreakDeadTimeConfig.OffStateIDLEMode = TIM_OSSI_DISABLE;
  sBreakDeadTimeConfig.LockLevel = TIM_LOCKLEVEL_OFF;
  sBreakDeadTimeConfig.DeadTime = 0;
  sBreakDeadTimeConfig.BreakState = TIM_BREAK_DISABLE;
  sBreakDeadTimeConfig.BreakPolarity = TIM_BREAKPOLARITY_HIGH;
  sBreakDeadTimeConfig.BreakFilter = 0;
  sBreakDeadTimeConfig.Break2State = TIM_BREAK2_DISABLE;
  sBreakDeadTimeConfig.Break2Polarity = TIM_BREAK2POLARITY_HIGH;
  sBreakDeadTimeConfig.Break2Filter = 0;
  sBreakDeadTimeConfig.AutomaticOutput = TIM_AUTOMATICOUTPUT_DISABLE;
  if (HAL_TIMEx_ConfigBreakDeadTime(&htim8, &sBreakDeadTimeConfig) != HAL_OK)
  {
    Error_Handler();
  }
  HAL_TIM_MspPostInit(&htim8);

}

static void MX_TIM12_Init(void)
{

  TIM_ClockConfigTypeDef sClockSourceConfig = {0};
  TIM_MasterConfigTypeDef sMasterConfig = {0};
  TIM_OC_InitTypeDef sConfigOC = {0};

  htim12.Instance = TIM12;
  htim12.Init.Prescaler = 0;
  htim12.Init.CounterMode = TIM_COUNTERMODE_UP;
  htim12.Init.Period = 24000-1;
  htim12.Init.ClockDivision = TIM_CLOCKDIVISION_DIV1;
  htim12.Init.AutoReloadPreload = TIM_AUTORELOAD_PRELOAD_ENABLE;
  if (HAL_TIM_Base_Init(&htim12) != HAL_OK)
  {
    Error_Handler();
  }
  sClockSourceConfig.ClockSource = TIM_CLOCKSOURCE_INTERNAL;
  if (HAL_TIM_ConfigClockSource(&htim12, &sClockSourceConfig) != HAL_OK)
  {
    Error_Handler();
  }
  if (HAL_TIM_PWM_Init(&htim12) != HAL_OK)
  {
    Error_Handler();
  }
  sMasterConfig.MasterOutputTrigger = TIM_TRGO_RESET;
  sMasterConfig.MasterSlaveMode = TIM_MASTERSLAVEMODE_DISABLE;
  if (HAL_TIMEx_MasterConfigSynchronization(&htim12, &sMasterConfig) != HAL_OK)
  {
    Error_Handler();
  }
  sConfigOC.OCMode = TIM_OCMODE_PWM1;
  sConfigOC.Pulse = 0;
  sConfigOC.OCPolarity = TIM_OCPOLARITY_HIGH;
  sConfigOC.OCFastMode = TIM_OCFAST_DISABLE;
  if (HAL_TIM_PWM_ConfigChannel(&htim12, &sConfigOC, TIM_CHANNEL_2) != HAL_OK)
  {
    Error_Handler();
  }
  HAL_TIM_MspPostInit(&htim12);

}

static void MX_TIM13_Init(void)
{

  TIM_OC_InitTypeDef sConfigOC = {0};

  htim13.Instance = TIM13;
  htim13.Init.Prescaler = 0;
  htim13.Init.CounterMode = TIM_COUNTERMODE_UP;
  htim13.Init.Period = 24000-1;
  htim13.Init.ClockDivision = TIM_CLOCKDIVISION_DIV1;
  htim13.Init.AutoReloadPreload = TIM_AUTORELOAD_PRELOAD_ENABLE;
  if (HAL_TIM_Base_Init(&htim13) != HAL_OK)
  {
    Error_Handler();
  }
  if (HAL_TIM_PWM_Init(&htim13) != HAL_OK)
  {
    Error_Handler();
  }
  sConfigOC.OCMode = TIM_OCMODE_PWM1;
  sConfigOC.Pulse = 0;
  sConfigOC.OCPolarity = TIM_OCPOLARITY_HIGH;
  sConfigOC.OCFastMode = TIM_OCFAST_DISABLE;
  if (HAL_TIM_PWM_ConfigChannel(&htim13, &sConfigOC, TIM_CHANNEL_1) != HAL_OK)
  {
    Error_Handler();
  }
  HAL_TIM_MspPostInit(&htim13);

}

static void MX_TIM14_Init(void)
{

  TIM_OC_InitTypeDef sConfigOC = {0};

  htim14.Instance = TIM14;
  htim14.Init.Prescaler = 0;
  htim14.Init.CounterMode = TIM_COUNTERMODE_UP;
  htim14.Init.Period = 24000-1;
  htim14.Init.ClockDivision = TIM_CLOCKDIVISION_DIV1;
  htim14.Init.AutoReloadPreload = TIM_AUTORELOAD_PRELOAD_ENABLE;
  if (HAL_TIM_Base_Init(&htim14) != HAL_OK)
  {
    Error_Handler();
  }
  if (HAL_TIM_PWM_Init(&htim14) != HAL_OK)
  {
    Error_Handler();
  }
  sConfigOC.OCMode = TIM_OCMODE_PWM1;
  sConfigOC.Pulse = 0;
  sConfigOC.OCPolarity = TIM_OCPOLARITY_HIGH;
  sConfigOC.OCFastMode = TIM_OCFAST_DISABLE;
  if (HAL_TIM_PWM_ConfigChannel(&htim14, &sConfigOC, TIM_CHANNEL_1) != HAL_OK)
  {
    Error_Handler();
  }
  HAL_TIM_MspPostInit(&htim14);

}

static void MX_TIM15_Init(void)
{

  TIM_ClockConfigTypeDef sClockSourceConfig = {0};
  TIM_MasterConfigTypeDef sMasterConfig = {0};
  TIM_OC_InitTypeDef sConfigOC = {0};
  TIM_BreakDeadTimeConfigTypeDef sBreakDeadTimeConfig = {0};

  htim15.Instance = TIM15;
  htim15.Init.Prescaler = 0;
  htim15.Init.CounterMode = TIM_COUNTERMODE_UP;
  htim15.Init.Period = 24000-1;
  htim15.Init.ClockDivision = TIM_CLOCKDIVISION_DIV1;
  htim15.Init.RepetitionCounter = 0;
  htim15.Init.AutoReloadPreload = TIM_AUTORELOAD_PRELOAD_ENABLE;
  if (HAL_TIM_Base_Init(&htim15) != HAL_OK)
  {
    Error_Handler();
  }
  sClockSourceConfig.ClockSource = TIM_CLOCKSOURCE_INTERNAL;
  if (HAL_TIM_ConfigClockSource(&htim15, &sClockSourceConfig) != HAL_OK)
  {
    Error_Handler();
  }
  if (HAL_TIM_PWM_Init(&htim15) != HAL_OK)
  {
    Error_Handler();
  }
  sMasterConfig.MasterOutputTrigger = TIM_TRGO_RESET;
  sMasterConfig.MasterSlaveMode = TIM_MASTERSLAVEMODE_DISABLE;
  if (HAL_TIMEx_MasterConfigSynchronization(&htim15, &sMasterConfig) != HAL_OK)
  {
    Error_Handler();
  }
  sConfigOC.OCMode = TIM_OCMODE_PWM1;
  sConfigOC.Pulse = 0;
  sConfigOC.OCPolarity = TIM_OCPOLARITY_HIGH;
  sConfigOC.OCNPolarity = TIM_OCNPOLARITY_HIGH;
  sConfigOC.OCFastMode = TIM_OCFAST_DISABLE;
  sConfigOC.OCIdleState = TIM_OCIDLESTATE_RESET;
  sConfigOC.OCNIdleState = TIM_OCNIDLESTATE_RESET;
  if (HAL_TIM_PWM_ConfigChannel(&htim15, &sConfigOC, TIM_CHANNEL_1) != HAL_OK)
  {
    Error_Handler();
  }
  if (HAL_TIM_PWM_ConfigChannel(&htim15, &sConfigOC, TIM_CHANNEL_2) != HAL_OK)
  {
    Error_Handler();
  }
  sBreakDeadTimeConfig.OffStateRunMode = TIM_OSSR_DISABLE;
  sBreakDeadTimeConfig.OffStateIDLEMode = TIM_OSSI_DISABLE;
  sBreakDeadTimeConfig.LockLevel = TIM_LOCKLEVEL_OFF;
  sBreakDeadTimeConfig.DeadTime = 0;
  sBreakDeadTimeConfig.BreakState = TIM_BREAK_DISABLE;
  sBreakDeadTimeConfig.BreakPolarity = TIM_BREAKPOLARITY_HIGH;
  sBreakDeadTimeConfig.BreakFilter = 0;
  sBreakDeadTimeConfig.AutomaticOutput = TIM_AUTOMATICOUTPUT_DISABLE;
  if (HAL_TIMEx_ConfigBreakDeadTime(&htim15, &sBreakDeadTimeConfig) != HAL_OK)
  {
    Error_Handler();
  }
  HAL_TIM_MspPostInit(&htim15);

}

static void MX_TIM16_Init(void)
{

  TIM_OC_InitTypeDef sConfigOC = {0};
  TIM_BreakDeadTimeConfigTypeDef sBreakDeadTimeConfig = {0};

  htim16.Instance = TIM16;
  htim16.Init.Prescaler = 0;
  htim16.Init.CounterMode = TIM_COUNTERMODE_UP;
  htim16.Init.Period = 24000-1;
  htim16.Init.ClockDivision = TIM_CLOCKDIVISION_DIV1;
  htim16.Init.RepetitionCounter = 0;
  htim16.Init.AutoReloadPreload = TIM_AUTORELOAD_PRELOAD_ENABLE;
  if (HAL_TIM_Base_Init(&htim16) != HAL_OK)
  {
    Error_Handler();
  }
  if (HAL_TIM_PWM_Init(&htim16) != HAL_OK)
  {
    Error_Handler();
  }
  sConfigOC.OCMode = TIM_OCMODE_PWM1;
  sConfigOC.Pulse = 0;
  sConfigOC.OCPolarity = TIM_OCPOLARITY_HIGH;
  sConfigOC.OCNPolarity = TIM_OCNPOLARITY_HIGH;
  sConfigOC.OCFastMode = TIM_OCFAST_DISABLE;
  sConfigOC.OCIdleState = TIM_OCIDLESTATE_RESET;
  sConfigOC.OCNIdleState = TIM_OCNIDLESTATE_RESET;
  if (HAL_TIM_PWM_ConfigChannel(&htim16, &sConfigOC, TIM_CHANNEL_1) != HAL_OK)
  {
    Error_Handler();
  }
  sBreakDeadTimeConfig.OffStateRunMode = TIM_OSSR_DISABLE;
  sBreakDeadTimeConfig.OffStateIDLEMode = TIM_OSSI_DISABLE;
  sBreakDeadTimeConfig.LockLevel = TIM_LOCKLEVEL_OFF;
  sBreakDeadTimeConfig.DeadTime = 0;
  sBreakDeadTimeConfig.BreakState = TIM_BREAK_DISABLE;
  sBreakDeadTimeConfig.BreakPolarity = TIM_BREAKPOLARITY_HIGH;
  sBreakDeadTimeConfig.BreakFilter = 0;
  sBreakDeadTimeConfig.AutomaticOutput = TIM_AUTOMATICOUTPUT_DISABLE;
  if (HAL_TIMEx_ConfigBreakDeadTime(&htim16, &sBreakDeadTimeConfig) != HAL_OK)
  {
    Error_Handler();
  }
  HAL_TIM_MspPostInit(&htim16);

}

static void MX_UART4_Init(void)
{

  LL_USART_InitTypeDef UART_InitStruct = {0};

  LL_GPIO_InitTypeDef GPIO_InitStruct = {0};
  RCC_PeriphCLKInitTypeDef PeriphClkInitStruct = {0};

  /** Initializes the peripherals clock
  */
  PeriphClkInitStruct.PeriphClockSelection = RCC_PERIPHCLK_UART4;
  PeriphClkInitStruct.Usart234578ClockSelection = RCC_USART234578CLKSOURCE_D2PCLK1;
  if (HAL_RCCEx_PeriphCLKConfig(&PeriphClkInitStruct) != HAL_OK)
  {
    Error_Handler();
  }

  /* Peripheral clock enable */
  LL_APB1_GRP1_EnableClock(LL_APB1_GRP1_PERIPH_UART4);

  LL_AHB4_GRP1_EnableClock(LL_AHB4_GRP1_PERIPH_GPIOC);
  /**UART4 GPIO Configuration
  PC10   ------> UART4_TX
  PC11   ------> UART4_RX
  */
  GPIO_InitStruct.Pin = LL_GPIO_PIN_10|LL_GPIO_PIN_11;
  GPIO_InitStruct.Mode = LL_GPIO_MODE_ALTERNATE;
  GPIO_InitStruct.Speed = LL_GPIO_SPEED_FREQ_LOW;
  GPIO_InitStruct.OutputType = LL_GPIO_OUTPUT_PUSHPULL;
  GPIO_InitStruct.Pull = LL_GPIO_PULL_NO;
  GPIO_InitStruct.Alternate = LL_GPIO_AF_8;
  LL_GPIO_Init(GPIOC, &GPIO_InitStruct);

  /* UART4 interrupt Init */
  NVIC_SetPriority(UART4_IRQn, NVIC_EncodePriority(NVIC_GetPriorityGrouping(),0, 0));
  NVIC_EnableIRQ(UART4_IRQn);

  UART_InitStruct.PrescalerValue = LL_USART_PRESCALER_DIV1;
  UART_InitStruct.BaudRate = 115200;
  UART_InitStruct.DataWidth = LL_USART_DATAWIDTH_8B;
  UART_InitStruct.StopBits = LL_USART_STOPBITS_1;
  UART_InitStruct.Parity = LL_USART_PARITY_NONE;
  UART_InitStruct.TransferDirection = LL_USART_DIRECTION_TX_RX;
  UART_InitStruct.HardwareFlowControl = LL_USART_HWCONTROL_NONE;
  UART_InitStruct.OverSampling = LL_USART_OVERSAMPLING_16;
  LL_USART_Init(UART4, &UART_InitStruct);
  LL_USART_DisableFIFO(UART4);
  LL_USART_SetTXFIFOThreshold(UART4, LL_USART_FIFOTHRESHOLD_1_8);
  LL_USART_SetRXFIFOThreshold(UART4, LL_USART_FIFOTHRESHOLD_1_8);
  LL_USART_ConfigAsyncMode(UART4);

  LL_USART_Enable(UART4);

  /* Polling UART4 initialisation */
  while((!(LL_USART_IsActiveFlag_TEACK(UART4))) || (!(LL_USART_IsActiveFlag_REACK(UART4))))
  {
  }

}

static void MX_GPIO_Init(void)
{
  GPIO_InitTypeDef GPIO_InitStruct = {0};

  /* GPIO Ports Clock Enable */
  __HAL_RCC_GPIOE_CLK_ENABLE();
  __HAL_RCC_GPIOC_CLK_ENABLE();
  __HAL_RCC_GPIOH_CLK_ENABLE();
  __HAL_RCC_GPIOA_CLK_ENABLE();
  __HAL_RCC_GPIOB_CLK_ENABLE();
  __HAL_RCC_GPIOD_CLK_ENABLE();

  /*Configure GPIO pin Output Level */
  HAL_GPIO_WritePin(GPIOE, TIM1_CH3_PH_Pin|TIM1_CH4_PH_Pin|TIM2_CH1_PH_Pin|TIM8_CH4_PH_Pin
                          |TIM12_CH2_PH_Pin|TIM13_CH1_PH_Pin|TIM14_CH1_PH_Pin|TIM15_CH1_PH_Pin
                          |TIM1_CH1_PH_Pin|TIM1_CH2_PH_Pin, GPIO_PIN_RESET);

  /*Configure GPIO pin Output Level */
  HAL_GPIO_WritePin(GPIOC, TIM4_CH4_PH_Pin|TIM5_CH2_PH_Pin|TIM5_CH3_PH_Pin|TIM4_CH3_PH_Pin, GPIO_PIN_RESET);

  /*Configure GPIO pin Output Level */
  HAL_GPIO_WritePin(GPIOB, TIM4_CH1_PH_Pin|TIM4_CH2_PH_Pin, GPIO_PIN_RESET);

  /*Configure GPIO pin Output Level */
  HAL_GPIO_WritePin(GPIOD, HRTIM_CHC1_PH_Pin|HRTIM_CHC2_PH_Pin|HRTIM_CHD1_PH_Pin|HRTIM_CHD2_PH_Pin
                          |TIM15_CH2_PH_Pin|TIM16_CH1_PH_Pin|LPTIM1_OUT_PH_Pin|HRTIM_CHA1_PH_Pin
                          |HRTIM_CHA2_PH_Pin|HRTIM_CHB1_PH_Pin|HRTIM_CHB2_PH_Pin, GPIO_PIN_RESET);

  /*Configure GPIO pins : TIM1_CH3_PH_Pin TIM1_CH4_PH_Pin TIM2_CH1_PH_Pin TIM8_CH4_PH_Pin
                           TIM12_CH2_PH_Pin TIM13_CH1_PH_Pin TIM14_CH1_PH_Pin TIM15_CH1_PH_Pin
                           TIM1_CH1_PH_Pin TIM1_CH2_PH_Pin */
  GPIO_InitStruct.Pin = TIM1_CH3_PH_Pin|TIM1_CH4_PH_Pin|TIM2_CH1_PH_Pin|TIM8_CH4_PH_Pin
                          |TIM12_CH2_PH_Pin|TIM13_CH1_PH_Pin|TIM14_CH1_PH_Pin|TIM15_CH1_PH_Pin
                          |TIM1_CH1_PH_Pin|TIM1_CH2_PH_Pin;
  GPIO_InitStruct.Mode = GPIO_MODE_OUTPUT_PP;
  GPIO_InitStruct.Pull = GPIO_NOPULL;
  GPIO_InitStruct.Speed = GPIO_SPEED_FREQ_LOW;
  HAL_GPIO_Init(GPIOE, &GPIO_InitStruct);

  /*Configure GPIO pins : TIM4_CH4_PH_Pin TIM5_CH2_PH_Pin TIM5_CH3_PH_Pin TIM4_CH3_PH_Pin */
  GPIO_InitStruct.Pin = TIM4_CH4_PH_Pin|TIM5_CH2_PH_Pin|TIM5_CH3_PH_Pin|TIM4_CH3_PH_Pin;
  GPIO_InitStruct.Mode = GPIO_MODE_OUTPUT_PP;
  GPIO_InitStruct.Pull = GPIO_NOPULL;
  GPIO_InitStruct.Speed = GPIO_SPEED_FREQ_LOW;
  HAL_GPIO_Init(GPIOC, &GPIO_InitStruct);

  /*Configure GPIO pins : TIM4_CH1_PH_Pin TIM4_CH2_PH_Pin */
  GPIO_InitStruct.Pin = TIM4_CH1_PH_Pin|TIM4_CH2_PH_Pin;
  GPIO_InitStruct.Mode = GPIO_MODE_OUTPUT_PP;
  GPIO_InitStruct.Pull = GPIO_NOPULL;
  GPIO_InitStruct.Speed = GPIO_SPEED_FREQ_LOW;
  HAL_GPIO_Init(GPIOB, &GPIO_InitStruct);

  /*Configure GPIO pins : HRTIM_CHC1_PH_Pin HRTIM_CHC2_PH_Pin HRTIM_CHD1_PH_Pin HRTIM_CHD2_PH_Pin
                           TIM15_CH2_PH_Pin TIM16_CH1_PH_Pin LPTIM1_OUT_PH_Pin HRTIM_CHA1_PH_Pin
                           HRTIM_CHA2_PH_Pin HRTIM_CHB1_PH_Pin HRTIM_CHB2_PH_Pin */
  GPIO_InitStruct.Pin = HRTIM_CHC1_PH_Pin|HRTIM_CHC2_PH_Pin|HRTIM_CHD1_PH_Pin|HRTIM_CHD2_PH_Pin
                          |TIM15_CH2_PH_Pin|TIM16_CH1_PH_Pin|LPTIM1_OUT_PH_Pin|HRTIM_CHA1_PH_Pin
                          |HRTIM_CHA2_PH_Pin|HRTIM_CHB1_PH_Pin|HRTIM_CHB2_PH_Pin;
  GPIO_InitStruct.Mode = GPIO_MODE_OUTPUT_PP;
  GPIO_InitStruct.Pull = GPIO_NOPULL;
  GPIO_InitStruct.Speed = GPIO_SPEED_FREQ_LOW;
  HAL_GPIO_Init(GPIOD, &GPIO_InitStruct);

}

/* USER CODE BEGIN 4 */

/**
* @brief CPU L1-Cache enable.
* @param None
* @retval None
*/
static void CPU_CACHE_Enable(void)
{
/* Enable I-Cache */
SCB_EnableICache();
/* Enable D-Cache */
SCB_EnableDCache();
}

/**
  * @brief  Compares two buffers.
  * @param  pBuffer1, pBuffer2: buffers to be compared.
  * @param  BufferLength: buffer's length
  * @retval 0  : pBuffer1 identical to pBuffer2
  *         >0 : pBuffer1 differs from pBuffer2
  */
static uint16_t Buffercmp(uint8_t* pBuffer1, uint8_t* pBuffer2, uint16_t BufferLength)
{
  while (BufferLength--)
  {
    if((*pBuffer1) != *pBuffer2)
    {
      return BufferLength;
    }
    pBuffer1++;
    pBuffer2++;
  }

  return 0;
}
/* USER CODE END 4 */

 /* MPU Configuration */

void MPU_Config(void)
{

  /* Disables the MPU */
  LL_MPU_Disable();

  /** Initializes and configures the Region and the memory to be protected
  */
  LL_MPU_ConfigRegion(LL_MPU_REGION_NUMBER0, 0x87, 0x0, LL_MPU_REGION_SIZE_4GB|LL_MPU_TEX_LEVEL0|LL_MPU_REGION_NO_ACCESS|LL_MPU_INSTRUCTION_ACCESS_DISABLE|LL_MPU_ACCESS_SHAREABLE|LL_MPU_ACCESS_NOT_CACHEABLE|LL_MPU_ACCESS_NOT_BUFFERABLE);
  /* Enables the MPU */
  LL_MPU_Enable(LL_MPU_CTRL_PRIVILEGED_DEFAULT);

}

void Error_Handler(void)
{
  __disable_irq();
  while (1)
  {
  }
}
